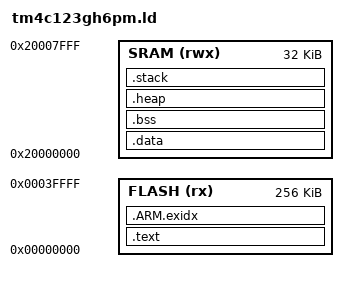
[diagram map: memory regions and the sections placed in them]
ENTRY(Reset_Handler)

MEMORY
{
    FLASH (rx) : ORIGIN = 0x00000000, LENGTH = 256K
    SRAM (rwx) : ORIGIN = 0x20000000, LENGTH = 32K
}

SECTIONS
{
    .text :
    {
        KEEP(*(.isr_vector))
        *(.text*)
        *(.rodata*)
        . = ALIGN(4);
        _etext = .;
    } > FLASH

    .ARM.exidx :
    {
        *(.ARM.exidx* .gnu.linkonce.armexidx.*)
    } > FLASH

    .data : AT (_etext)
    {
        _data = .;
        *(.data*)
        . = ALIGN(4);
        _edata = .;
    } > SRAM

    .bss :
    {
        _bss = .;
        *(.bss*)
        *(COMMON)
        . = ALIGN(4);
        _ebss = .;
    } > SRAM

    .heap :
    {
        _heap = .;
        . = . + 0x2000;
        _eheap = .;
    } > SRAM

    .stack :
    {
        . = . + 0x1000;
        _estack = .;
    } > SRAM
}
